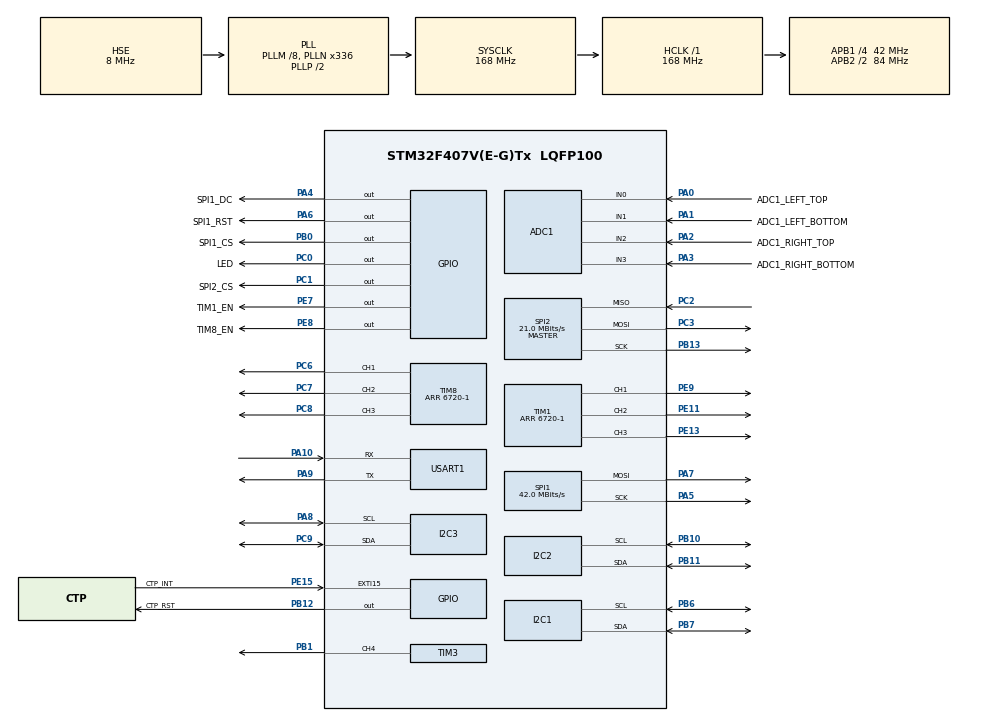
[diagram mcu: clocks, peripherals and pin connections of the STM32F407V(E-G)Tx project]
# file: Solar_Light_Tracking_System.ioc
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ADC1.Channel-0\#ChannelRegularConversion=ADC_CHANNEL_0
ADC1.Channel-1\#ChannelRegularConversion=ADC_CHANNEL_1
ADC1.Channel-2\#ChannelRegularConversion=ADC_CHANNEL_2
ADC1.Channel-3\#ChannelRegularConversion=ADC_CHANNEL_3
ADC1.ContinuousConvMode=ENABLE
ADC1.DMAContinuousRequests=ENABLE
ADC1.EnableAnalogWatchDog=false
ADC1.InjNumberOfConversion=0
ADC1.NbrOfConversion=4
ADC1.NbrOfConversionFlag=1
ADC1.Rank-0\#ChannelRegularConversion=1
ADC1.Rank-1\#ChannelRegularConversion=2
ADC1.Rank-2\#ChannelRegularConversion=3
ADC1.Rank-3\#ChannelRegularConversion=4
ADC1.SamplingTime-0\#ChannelRegularConversion=ADC_SAMPLETIME_144CYCLES
ADC1.SamplingTime-1\#ChannelRegularConversion=ADC_SAMPLETIME_144CYCLES
ADC1.SamplingTime-2\#ChannelRegularConversion=ADC_SAMPLETIME_144CYCLES
ADC1.SamplingTime-3\#ChannelRegularConversion=ADC_SAMPLETIME_144CYCLES
ADC1.ScanConvMode=ENABLE
ADC1.master=1
Dma.ADC1.0.Direction=DMA_PERIPH_TO_MEMORY
Dma.ADC1.0.FIFOMode=DMA_FIFOMODE_DISABLE
Dma.ADC1.0.Instance=DMA2_Stream0
Dma.ADC1.0.MemDataAlignment=DMA_MDATAALIGN_HALFWORD
Dma.ADC1.0.MemInc=DMA_MINC_ENABLE
Dma.ADC1.0.Mode=DMA_CIRCULAR
Dma.ADC1.0.PeriphDataAlignment=DMA_PDATAALIGN_HALFWORD
Dma.ADC1.0.PeriphInc=DMA_PINC_DISABLE
Dma.ADC1.0.Priority=DMA_PRIORITY_MEDIUM
Dma.Request0=ADC1
Dma.Request1=SPI1_TX
Dma.Request2=SPI2_TX
Dma.Request3=SPI2_RX
Dma.SPI1_TX.1.Direction=DMA_MEMORY_TO_PERIPH
Dma.SPI1_TX.1.FIFOMode=DMA_FIFOMODE_DISABLE
Dma.SPI1_TX.1.Instance=DMA2_Stream5
Dma.SPI1_TX.1.MemDataAlignment=DMA_MDATAALIGN_HALFWORD
Dma.SPI1_TX.1.MemInc=DMA_MINC_ENABLE
Dma.SPI1_TX.1.Mode=DMA_NORMAL
Dma.SPI1_TX.1.PeriphDataAlignment=DMA_PDATAALIGN_HALFWORD
Dma.SPI1_TX.1.PeriphInc=DMA_PINC_DISABLE
Dma.SPI1_TX.1.Priority=DMA_PRIORITY_LOW
Dma.SPI2_RX.3.Direction=DMA_PERIPH_TO_MEMORY
Dma.SPI2_RX.3.FIFOMode=DMA_FIFOMODE_DISABLE
Dma.SPI2_RX.3.Instance=DMA1_Stream3
Dma.SPI2_RX.3.MemDataAlignment=DMA_MDATAALIGN_BYTE
Dma.SPI2_RX.3.MemInc=DMA_MINC_ENABLE
Dma.SPI2_RX.3.Mode=DMA_NORMAL
Dma.SPI2_RX.3.PeriphDataAlignment=DMA_PDATAALIGN_BYTE
Dma.SPI2_RX.3.PeriphInc=DMA_PINC_DISABLE
Dma.SPI2_RX.3.Priority=DMA_PRIORITY_HIGH
Dma.SPI2_TX.2.Direction=DMA_MEMORY_TO_PERIPH
Dma.SPI2_TX.2.FIFOMode=DMA_FIFOMODE_DISABLE
Dma.SPI2_TX.2.Instance=DMA1_Stream4
Dma.SPI2_TX.2.MemDataAlignment=DMA_MDATAALIGN_BYTE
Dma.SPI2_TX.2.MemInc=DMA_MINC_ENABLE
Dma.SPI2_TX.2.Mode=DMA_NORMAL
Dma.SPI2_TX.2.PeriphDataAlignment=DMA_PDATAALIGN_BYTE
Dma.SPI2_TX.2.PeriphInc=DMA_PINC_DISABLE
Dma.SPI2_TX.2.Priority=DMA_PRIORITY_HIGH
FREERTOS.Queues01=Smapling,16,SmaplingData_t,0,Dynamic,NULL,NULL;SmapToSystem,16,SmaplingData_t,0,Dynamic,NULL,NULL;SmapSystemToMotor,16,AppMotorCommand,0,Dynamic,NULL,NULL
FREERTOS.Tasks01=DebugTask,8,512,StartDebugTask,As weak,NULL,Dynamic,NULL,NULL;UiTask,8,2048,StartUiTask,As weak,NULL,Dynamic,NULL,NULL;MotorTask,24,512,StartMotorTask,As weak,NULL,Dynamic,NULL,NULL;SmaplingTask,24,512,StartSmaplingTask,As weak,NULL,Dynamic,NULL,NULL;SystemStateTask,8,512,StartSystemStateTask,As weak,NULL,Dynamic,NULL,NULL
FREERTOS.configTOTAL_HEAP_SIZE=30720
I2C1.I2C_Mode=I2C_Fast
I2C2.I2C_Mode=I2C_Fast
I2C3.I2C_Mode=I2C_Fast
Mcu.Family=STM32F4
Mcu.Name=STM32F407V(E-G)Tx
Mcu.Package=LQFP100
NVIC.DMA1_Stream3_IRQn=true\:5\:0\:false\:false\:true\:true\:false\:true\:true
NVIC.DMA1_Stream4_IRQn=true\:5\:0\:false\:false\:true\:true\:false\:true\:true
NVIC.DMA2_Stream0_IRQn=true\:5\:0\:false\:false\:true\:true\:false\:true\:true
NVIC.DMA2_Stream5_IRQn=true\:5\:0\:true\:false\:true\:true\:false\:true\:true
NVIC.EXTI15_10_IRQn=true\:5\:0\:false\:false\:true\:true\:true\:true\:true
NVIC.PriorityGroup=NVIC_PRIORITYGROUP_4
NVIC.RTC_WKUP_IRQn=true\:10\:0\:true\:false\:true\:true\:true\:true\:true
NVIC.TIM6_DAC_IRQn=true\:15\:0\:false\:false\:true\:false\:false\:true\:true
NVIC.TimeBase=TIM6_DAC_IRQn
NVIC.TimeBaseIP=TIM6
PA0-WKUP.GPIO_Label=ADC1_LEFT_TOP
PA0-WKUP.Signal=ADCx_IN0
PA1.GPIO_Label=ADC1_LEFT_BOTTOM
PA1.Signal=ADCx_IN1
PA10.Mode=Asynchronous
PA10.Signal=USART1_RX
PA13.Mode=Serial_Wire
PA13.Signal=SYS_JTMS-SWDIO
PA14.Mode=Serial_Wire
PA14.Signal=SYS_JTCK-SWCLK
PA2.GPIO_Label=ADC1_RIGHT_TOP
PA2.Signal=ADCx_IN2
PA3.GPIO_Label=ADC1_RIGHT_BOTTOM
PA3.Signal=ADCx_IN3
PA4.GPIO_Label=SPI1_DC
PA4.GPIO_Speed=GPIO_SPEED_FREQ_MEDIUM
PA4.Signal=GPIO_Output
PA5.Mode=TX_Only_Simplex_Unidirect_Master
PA5.Signal=SPI1_SCK
PA6.GPIO_Label=SPI1_RST
PA6.GPIO_Speed=GPIO_SPEED_FREQ_MEDIUM
PA6.Signal=GPIO_Output
PA7.Mode=TX_Only_Simplex_Unidirect_Master
PA7.Signal=SPI1_MOSI
PA8.Mode=I2C
PA8.Signal=I2C3_SCL
PA9.Mode=Asynchronous
PA9.Signal=USART1_TX
PB0.GPIO_Label=SPI1_CS
PB0.GPIO_Speed=GPIO_SPEED_FREQ_MEDIUM
PB0.PinState=GPIO_PIN_SET
PB0.Signal=GPIO_Output
PB1.Signal=S_TIM3_CH4
PB10.GPIO_Pu=GPIO_NOPULL
PB10.Mode=I2C
PB10.Signal=I2C2_SCL
PB11.GPIO_Pu=GPIO_NOPULL
PB11.Mode=I2C
PB11.Signal=I2C2_SDA
PB12.GPIO_Label=CTP_RST
PB12.GPIO_Speed=GPIO_SPEED_FREQ_MEDIUM
PB12.PinState=GPIO_PIN_SET
PB12.Signal=GPIO_Output
PB13.Mode=Full_Duplex_Master
PB13.Signal=SPI2_SCK
PB6.Mode=I2C
PB6.Signal=I2C1_SCL
PB7.Mode=I2C
PB7.Signal=I2C1_SDA
PC0.GPIO_Label=LED
PC0.PinState=GPIO_PIN_SET
PC0.Signal=GPIO_Output
PC1.GPIO_Label=SPI2_CS
PC1.GPIO_Speed=GPIO_SPEED_FREQ_MEDIUM
PC1.PinState=GPIO_PIN_SET
PC1.Signal=GPIO_Output
PC2.Mode=Full_Duplex_Master
PC2.Signal=SPI2_MISO
PC3.Mode=Full_Duplex_Master
PC3.Signal=SPI2_MOSI
PC6.Signal=S_TIM8_CH1
PC7.Signal=S_TIM8_CH2
PC8.Signal=S_TIM8_CH3
PC9.Mode=I2C
PC9.Signal=I2C3_SDA
PE11.Signal=S_TIM1_CH2
PE13.Signal=S_TIM1_CH3
PE15.GPIO_Label=CTP_INT
PE15.GPIO_ModeDefaultEXTI=GPIO_MODE_IT_FALLING
PE15.GPIO_PuPd=GPIO_PULLUP
PE15.Signal=GPXTI15
PE7.GPIO_Label=TIM1_EN
PE7.GPIO_ModeDefaultOutputPP=GPIO_MODE_OUTPUT_PP
PE7.GPIO_PuPd=GPIO_NOPULL
PE7.GPIO_Speed=GPIO_SPEED_FREQ_LOW
PE7.PinState=GPIO_PIN_RESET
PE7.Signal=GPIO_Output
PE8.GPIO_Label=TIM8_EN
PE8.GPIO_ModeDefaultOutputPP=GPIO_MODE_OUTPUT_PP
PE8.GPIO_PuPd=GPIO_NOPULL
PE8.GPIO_Speed=GPIO_SPEED_FREQ_LOW
PE8.PinState=GPIO_PIN_RESET
PE8.Signal=GPIO_Output
PE9.Signal=S_TIM1_CH1
PH0-OSC_IN.Mode=HSE-External-Oscillator
PH0-OSC_IN.Signal=RCC_OSC_IN
PH1-OSC_OUT.Mode=HSE-External-Oscillator
PH1-OSC_OUT.Signal=RCC_OSC_OUT
ProjectManager.HeapSize=0x4000
ProjectManager.StackSize=0x2000
ProjectManager.TargetToolchain=CMake
RCC.48MHZClocksFreq_Value=84000000
RCC.AHBFreq_Value=168000000
RCC.APB1CLKDivider=RCC_HCLK_DIV4
RCC.APB1Freq_Value=42000000
RCC.APB1TimFreq_Value=84000000
RCC.APB2CLKDivider=RCC_HCLK_DIV2
RCC.APB2Freq_Value=84000000
RCC.APB2TimFreq_Value=168000000
RCC.CortexFreq_Value=168000000
RCC.HCLKFreq_Value=168000000
RCC.HSE_VALUE=8000000
RCC.HSI_VALUE=16000000
RCC.LSE_VALUE=32768
RCC.PLLM=8
RCC.PLLN=336
RCC.PLLSourceVirtual=RCC_PLLSOURCE_HSE
RCC.SYSCLKFreq_VALUE=168000000
RCC.SYSCLKSource=RCC_SYSCLKSOURCE_PLLCLK
RCC.VCOOutputFreq_Value=336000000
RTC.AsynchPrediv=124
RTC.WakeUpClock=RTC_WAKEUPCLOCK_CK_SPRE_16BITS
RTC.WakeUpCounter=2
SH.ADCx_IN0.0=ADC1_IN0,IN0
SH.ADCx_IN1.0=ADC1_IN1,IN1
SH.ADCx_IN2.0=ADC1_IN2,IN2
SH.ADCx_IN3.0=ADC1_IN3,IN3
SH.S_TIM1_CH1.0=TIM1_CH1,PWM Generation1 CH1
SH.S_TIM1_CH2.0=TIM1_CH2,PWM Generation2 CH2
SH.S_TIM1_CH3.0=TIM1_CH3,PWM Generation3 CH3
SH.S_TIM3_CH4.0=TIM3_CH4,PWM Generation4 CH4
SH.S_TIM8_CH1.0=TIM8_CH1,PWM Generation1 CH1
SH.S_TIM8_CH2.0=TIM8_CH2,PWM Generation2 CH2
SH.S_TIM8_CH3.0=TIM8_CH3,PWM Generation3 CH3
SPI1.BaudRatePrescaler=SPI_BAUDRATEPRESCALER_2
SPI1.CalculateBaudRate=42.0 MBits/s
SPI1.Direction=SPI_DIRECTION_2LINES
SPI1.Mode=SPI_MODE_MASTER
SPI1.VirtualType=VM_MASTER
SPI2.CalculateBaudRate=21.0 MBits/s
SPI2.Direction=SPI_DIRECTION_2LINES
SPI2.FirstBit=SPI_FIRSTBIT_MSB
SPI2.Mode=SPI_MODE_MASTER
SPI2.VirtualType=VM_MASTER
STMicroelectronics.X-CUBE-ALGOBUILD.1.5.0.LibraryCcDSPOoLibraryJjDSPOoLibrary=true
TIM1.Channel-PWM\ Generation1\ CH1=TIM_CHANNEL_1
TIM1.Channel-PWM\ Generation2\ CH2=TIM_CHANNEL_2
TIM1.Channel-PWM\ Generation3\ CH3=TIM_CHANNEL_3
TIM1.Period=6720-1
TIM3.Channel-PWM\ Generation4\ CH4=TIM_CHANNEL_4
TIM3.Period=100-1
TIM3.Prescaler=840-1
TIM8.Channel-PWM\ Generation1\ CH1=TIM_CHANNEL_1
TIM8.Channel-PWM\ Generation2\ CH2=TIM_CHANNEL_2
TIM8.Channel-PWM\ Generation3\ CH3=TIM_CHANNEL_3
TIM8.Period=6720-1
USART1.VirtualMode=VM_ASYNC
VP_FREERTOS_VS_CMSIS_V2.Mode=CMSIS_V2
VP_RTC_VS_RTC_Activate.Mode=RTC_Enabled
VP_RTC_VS_RTC_WakeUp_intern.Mode=WakeUp
VP_STMicroelectronics.X-CUBE-ALGOBUILD_VS_DSPOoLibraryJjLibrary_1.5.0_1.5.0.Mode=DSPOoLibraryJjLibrary
VP_SYS_VS_tim6.Mode=TIM6
VP_TIM1_VS_ClockSourceINT.Mode=Internal
VP_TIM3_VS_ClockSourceINT.Mode=Internal
VP_TIM8_VS_ClockSourceINT.Mode=Internal
board=custom

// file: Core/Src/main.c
/* USER CODE BEGIN Header */
/**
  ******************************************************************************
  * @file           : main.c
  * @brief          : Main program body
  ******************************************************************************
  * @attention
  *
  * Copyright (c) 2026 STMicroelectronics.
  * All rights reserved.
  *
  * This software is licensed under terms that can be found in the LICENSE file
  * in the root directory of this software component.
  * If no LICENSE file comes with this software, it is provided AS-IS.
  *
  ******************************************************************************
  */
/* USER CODE END Header */
#include "main.h"
#include "cmsis_os.h"
#include "adc.h"
#include "dma.h"
#include "i2c.h"
#include "rtc.h"
#include "spi.h"
#include "tim.h"
#include "usart.h"
#include "gpio.h"

/* USER CODE BEGIN Includes */
#include "lvgl.h"
#include "lv_port_indev.h"
#include "lv_port_lcd_stm32.h"
#include "user_home.h"
#include "SimpleFOC_Motor.h"
/* USER CODE END Includes */

void SystemClock_Config(void);
void MX_FREERTOS_Init(void);

int main(void)
{

  /* MCU Configuration--------------------------------------------------------*/

  /* Reset of all peripherals, Initializes the Flash interface and the Systick. */
  HAL_Init();

  /* Configure the system clock */
  SystemClock_Config();

  /* Initialize all configured peripherals */
  MX_GPIO_Init();
  MX_DMA_Init();
  MX_SPI1_Init();
  MX_USART1_UART_Init();
  MX_I2C2_Init();
  MX_TIM1_Init();
  MX_TIM8_Init();
  MX_ADC1_Init();
  MX_SPI2_Init();
  MX_I2C1_Init();
  MX_I2C3_Init();
  MX_RTC_Init();
  MX_TIM3_Init();
  /* USER CODE BEGIN 2 */

  /*
   * 只初始化两组定时器 PWM，不在这里使能电机。
   * SimpleFOC_Motor_Init() 会把六路 PWM 设为约 50%，并保持两个 EN 为关闭电平。
   */
  if (SimpleFOC_Motor_Init() != HAL_OK)
  {
    Error_Handler();
  }

  /* USER CODE END 2 */

  /* Init scheduler */
  osKernelInitialize();  /* Call init function for freertos objects (in cmsis_os2.c) */
  MX_FREERTOS_Init();

  /* Start scheduler */
  osKernelStart();

  /* We should never get here as control is now taken by the scheduler */

  /* Infinite loop */
  while (1)
  {

  }
}

void SystemClock_Config(void)
{
  RCC_OscInitTypeDef RCC_OscInitStruct = {0};
  RCC_ClkInitTypeDef RCC_ClkInitStruct = {0};

  /** Configure the main internal regulator output voltage
  */
  __HAL_RCC_PWR_CLK_ENABLE();
  __HAL_PWR_VOLTAGESCALING_CONFIG(PWR_REGULATOR_VOLTAGE_SCALE1);

  /** Initializes the RCC Oscillators according to the specified parameters
  * in the RCC_OscInitTypeDef structure.
  */
  RCC_OscInitStruct.OscillatorType = RCC_OSCILLATORTYPE_LSI|RCC_OSCILLATORTYPE_HSE;
  RCC_OscInitStruct.HSEState = RCC_HSE_ON;
  RCC_OscInitStruct.LSIState = RCC_LSI_ON;
  RCC_OscInitStruct.PLL.PLLState = RCC_PLL_ON;
  RCC_OscInitStruct.PLL.PLLSource = RCC_PLLSOURCE_HSE;
  RCC_OscInitStruct.PLL.PLLM = 8;
  RCC_OscInitStruct.PLL.PLLN = 336;
  RCC_OscInitStruct.PLL.PLLP = RCC_PLLP_DIV2;
  RCC_OscInitStruct.PLL.PLLQ = 4;
  if (HAL_RCC_OscConfig(&RCC_OscInitStruct) != HAL_OK)
  {
    Error_Handler();
  }

  /** Initializes the CPU, AHB and APB buses clocks
  */
  RCC_ClkInitStruct.ClockType = RCC_CLOCKTYPE_HCLK|RCC_CLOCKTYPE_SYSCLK
                              |RCC_CLOCKTYPE_PCLK1|RCC_CLOCKTYPE_PCLK2;
  RCC_ClkInitStruct.SYSCLKSource = RCC_SYSCLKSOURCE_PLLCLK;
  RCC_ClkInitStruct.AHBCLKDivider = RCC_SYSCLK_DIV1;
  RCC_ClkInitStruct.APB1CLKDivider = RCC_HCLK_DIV4;
  RCC_ClkInitStruct.APB2CLKDivider = RCC_HCLK_DIV2;

  if (HAL_RCC_ClockConfig(&RCC_ClkInitStruct, FLASH_LATENCY_5) != HAL_OK)
  {
    Error_Handler();
  }
}

void HAL_TIM_PeriodElapsedCallback(TIM_HandleTypeDef *htim)
{
  if (htim->Instance == TIM6)
  {
    HAL_IncTick();
  }
}

void Error_Handler(void)
{
  __disable_irq();
  while (1)
  {
  }
}

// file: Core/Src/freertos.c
/* USER CODE BEGIN Header */
/**
  ******************************************************************************
  * File Name          : freertos.c
  * Description        : Code for freertos applications
  ******************************************************************************
  * @attention
  *
  * Copyright (c) 2026 STMicroelectronics.
  * All rights reserved.
  *
  * This software is licensed under terms that can be found in the LICENSE file
  * in the root directory of this software component.
  * If no LICENSE file comes with this software, it is provided AS-IS.
  *
  ******************************************************************************
  */
/* USER CODE END Header */

#include "FreeRTOS.h"
#include "task.h"
#include "main.h"
#include "cmsis_os.h"

/* USER CODE BEGIN Includes */
#include "SimpleFOC_Motor.h"
#include "SmaplingTypes.h"
#include "AppMotorCommand.h"

/* USER CODE END Includes */

/* Definitions for DebugTask */
osThreadId_t DebugTaskHandle;
const osThreadAttr_t DebugTask_attributes = {
  .name = "DebugTask",
  .stack_size = 512 * 4,
  .priority = (osPriority_t) osPriorityLow,
};
/* Definitions for UiTask */
osThreadId_t UiTaskHandle;
const osThreadAttr_t UiTask_attributes = {
  .name = "UiTask",
  .stack_size = 2048 * 4,
  .priority = (osPriority_t) osPriorityLow,
};
/* Definitions for MotorTask */
osThreadId_t MotorTaskHandle;
const osThreadAttr_t MotorTask_attributes = {
  .name = "MotorTask",
  .stack_size = 512 * 4,
  .priority = (osPriority_t) osPriorityNormal,
};
/* Definitions for SmaplingTask */
osThreadId_t SmaplingTaskHandle;
const osThreadAttr_t SmaplingTask_attributes = {
  .name = "SmaplingTask",
  .stack_size = 512 * 4,
  .priority = (osPriority_t) osPriorityNormal,
};
/* Definitions for SystemStateTask */
osThreadId_t SystemStateTaskHandle;
const osThreadAttr_t SystemStateTask_attributes = {
  .name = "SystemStateTask",
  .stack_size = 512 * 4,
  .priority = (osPriority_t) osPriorityLow,
};
/* Definitions for Smapling */
osMessageQueueId_t SmaplingHandle;
const osMessageQueueAttr_t Smapling_attributes = {
  .name = "Smapling"
};
/* Definitions for SmapToSystem */
osMessageQueueId_t SmapToSystemHandle;
const osMessageQueueAttr_t SmapToSystem_attributes = {
  .name = "SmapToSystem"
};
/* Definitions for SmapSystemToMotor */
osMessageQueueId_t SmapSystemToMotorHandle;
const osMessageQueueAttr_t SmapSystemToMotor_attributes = {
  .name = "SmapSystemToMotor"
};

void StartDebugTask(void *argument);
void StartUiTask(void *argument);
void StartMotorTask(void *argument);
void StartSmaplingTask(void *argument);
void StartSystemStateTask(void *argument);

void MX_FREERTOS_Init(void); /* (MISRA C 2004 rule 8.1) */

void MX_FREERTOS_Init(void) {

  /* Create the queue(s) */
  /* creation of Smapling */
  SmaplingHandle = osMessageQueueNew (16, sizeof(SmaplingData_t), &Smapling_attributes);

  /* creation of SmapToSystem */
  SmapToSystemHandle = osMessageQueueNew (16, sizeof(SmaplingData_t), &SmapToSystem_attributes);

  /* creation of SmapSystemToMotor */
  SmapSystemToMotorHandle = osMessageQueueNew (16, sizeof(AppMotorCommand), &SmapSystemToMotor_attributes);

  /* Create the thread(s) */
  /* creation of DebugTask */
  DebugTaskHandle = osThreadNew(StartDebugTask, NULL, &DebugTask_attributes);

  /* creation of UiTask */
  UiTaskHandle = osThreadNew(StartUiTask, NULL, &UiTask_attributes);

  /* creation of MotorTask */
  MotorTaskHandle = osThreadNew(StartMotorTask, NULL, &MotorTask_attributes);

  /* creation of SmaplingTask */
  SmaplingTaskHandle = osThreadNew(StartSmaplingTask, NULL, &SmaplingTask_attributes);

  /* creation of SystemStateTask */
  SystemStateTaskHandle = osThreadNew(StartSystemStateTask, NULL, &SystemStateTask_attributes);

}

__weak void StartDebugTask(void *argument)
{
  for(;;)
  {
    osDelay(1);
  }
}

__weak void StartUiTask(void *argument)
{
  for(;;)
  {
    osDelay(1);
  }
}

__weak void StartMotorTask(void *argument)
{
  for(;;)
  {
    osDelay(1);
  }
}

__weak void StartSmaplingTask(void *argument)
{
  for(;;)
  {
    osDelay(1);
  }
}

__weak void StartSystemStateTask(void *argument)
{
  for(;;)
  {
    osDelay(1);
  }
}
